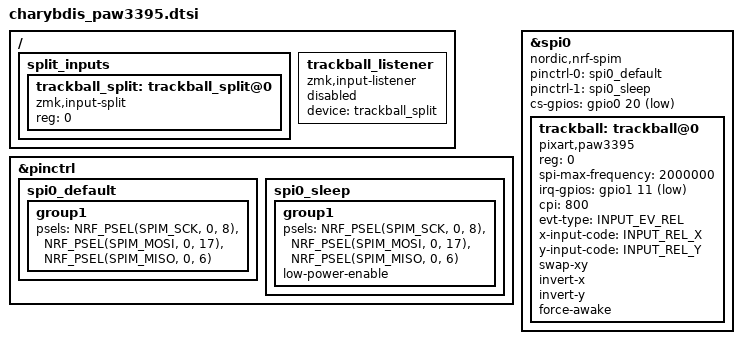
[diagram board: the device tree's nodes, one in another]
/*
 * PAW3395 trackball sensor for the right half (replaces charybdis_pmw3610.dtsi).
 *
 * PAW3395 uses 4-wire SPI. Pins follow the labels on the controller shield's
 * "SPI" header (olidacombe nice!nano holder), so every shield pad goes to the
 * sensor pad with the same name; only MOTION needs one extra wire.
 *
 *   Signal   nRF52840  SuperMini pin       Shield SPI pad   Sensor board pad
 *   VCC      VCC 3.3V  VCC                 VCC              VIN
 *   CS       P0.20     D3                  CS               CS
 *   MOSI     P0.17     D2                  MOSI             MOSI
 *   SCLK     P0.08     D0 (RX)             SCLK             SCLK
 *   MISO     P0.06     D1 (TX)             MISO             MISO
 *   GND      GND       GND                 GND              GND
 *   MOTION   P1.11     "1.11" (D14)        - (extra wire)   MOT
 *
 * Note: with the old PMW3610 the "MOSI" pad carried SDIO and the "MISO" pad
 * carried MOTION; that is why the stock pmw3610 dtsi used P0.17 and P0.06.
 */

&pinctrl {
    spi0_default: spi0_default {
        group1 {
            psels = <NRF_PSEL(SPIM_SCK, 0, 8)>,
                <NRF_PSEL(SPIM_MOSI, 0, 17)>,
                <NRF_PSEL(SPIM_MISO, 0, 6)>;
        };
    };

    spi0_sleep: spi0_sleep {
        group1 {
            psels = <NRF_PSEL(SPIM_SCK, 0, 8)>,
                <NRF_PSEL(SPIM_MOSI, 0, 17)>,
                <NRF_PSEL(SPIM_MISO, 0, 6)>;
            low-power-enable;
        };
    };
};

#include <zephyr/dt-bindings/input/input-event-codes.h>

&spi0 {
    status = "okay";
    compatible = "nordic,nrf-spim";
    pinctrl-0 = <&spi0_default>;
    pinctrl-1 = <&spi0_sleep>;
    pinctrl-names = "default", "sleep";
    cs-gpios = <&gpio0 20 GPIO_ACTIVE_LOW>;

    trackball: trackball@0 {
        status = "okay";
        compatible = "pixart,paw3395";
        reg = <0>;
        /* ~10 cm FFC: 2 MHz is conservative; driver example uses 4 MHz */
        spi-max-frequency = <2000000>;
        irq-gpios = <&gpio1 11 (GPIO_ACTIVE_LOW | GPIO_PULL_UP)>;
        cpi = <800>; /* 50..26000, step 50 */
        evt-type = <INPUT_EV_REL>;
        x-input-code = <INPUT_REL_X>;
        y-input-code = <INPUT_REL_Y>;

        /* Orientation depends on how the sensor sits on the new PCB.
           Start with the PMW3610 values; flip as needed after first test. */
        swap-xy;
        invert-x;
        invert-y;

        /* Full performance while ZMK is ACTIVE, drops back when IDLE/SLEEP */
        force-awake;
    };
};

/ {
    split_inputs {
        #address-cells = <1>;
        #size-cells = <0>;

        trackball_split: trackball_split@0 {
            compatible = "zmk,input-split";
            reg = <0>;
        };
    };

    trackball_listener: trackball_listener {
        compatible = "zmk,input-listener";
        status = "disabled"; // overridden on central
        device = <&trackball_split>;
    };
};
